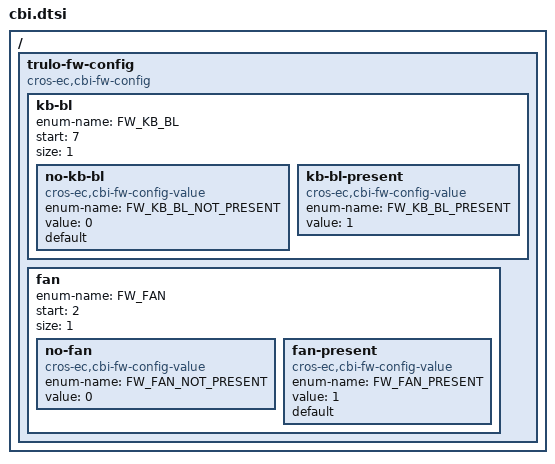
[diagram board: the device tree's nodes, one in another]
/* Copyright 2025 The ChromiumOS Authors
 * Use of this source code is governed by a BSD-style license that can be
 * found in the LICENSE file.
 */

/ {
/* Pujjocento-specific fw_config fields. */
	trulo-fw-config {
		compatible = "cros-ec,cbi-fw-config";
		/*
		 * FW_CONFIG field to enable KB backlight or not.
		 */
		kb-bl {
			enum-name = "FW_KB_BL";
			start = <7>;
			size = <1>;

			no-kb-bl {
				compatible = "cros-ec,cbi-fw-config-value";
				enum-name = "FW_KB_BL_NOT_PRESENT";
				value = <0>;
				default;
			};
			kb-bl-present {
				compatible = "cros-ec,cbi-fw-config-value";
				enum-name = "FW_KB_BL_PRESENT";
				value = <1>;
			};
		};

		/*
		 * FW_CONFIG field to enable fan or not.
		 */
		fan {
			enum-name = "FW_FAN";
			start = <2>;
			size = <1>;

			no-fan {
				compatible = "cros-ec,cbi-fw-config-value";
				enum-name = "FW_FAN_NOT_PRESENT";
				value = <0>;
			};
			fan-present {
				compatible = "cros-ec,cbi-fw-config-value";
				enum-name = "FW_FAN_PRESENT";
				value = <1>;
				/*
				 * Set as default so that unprovisioned
				 * configs will run the fan regardless.
				 */
				default;
			};
		};
	};
};
